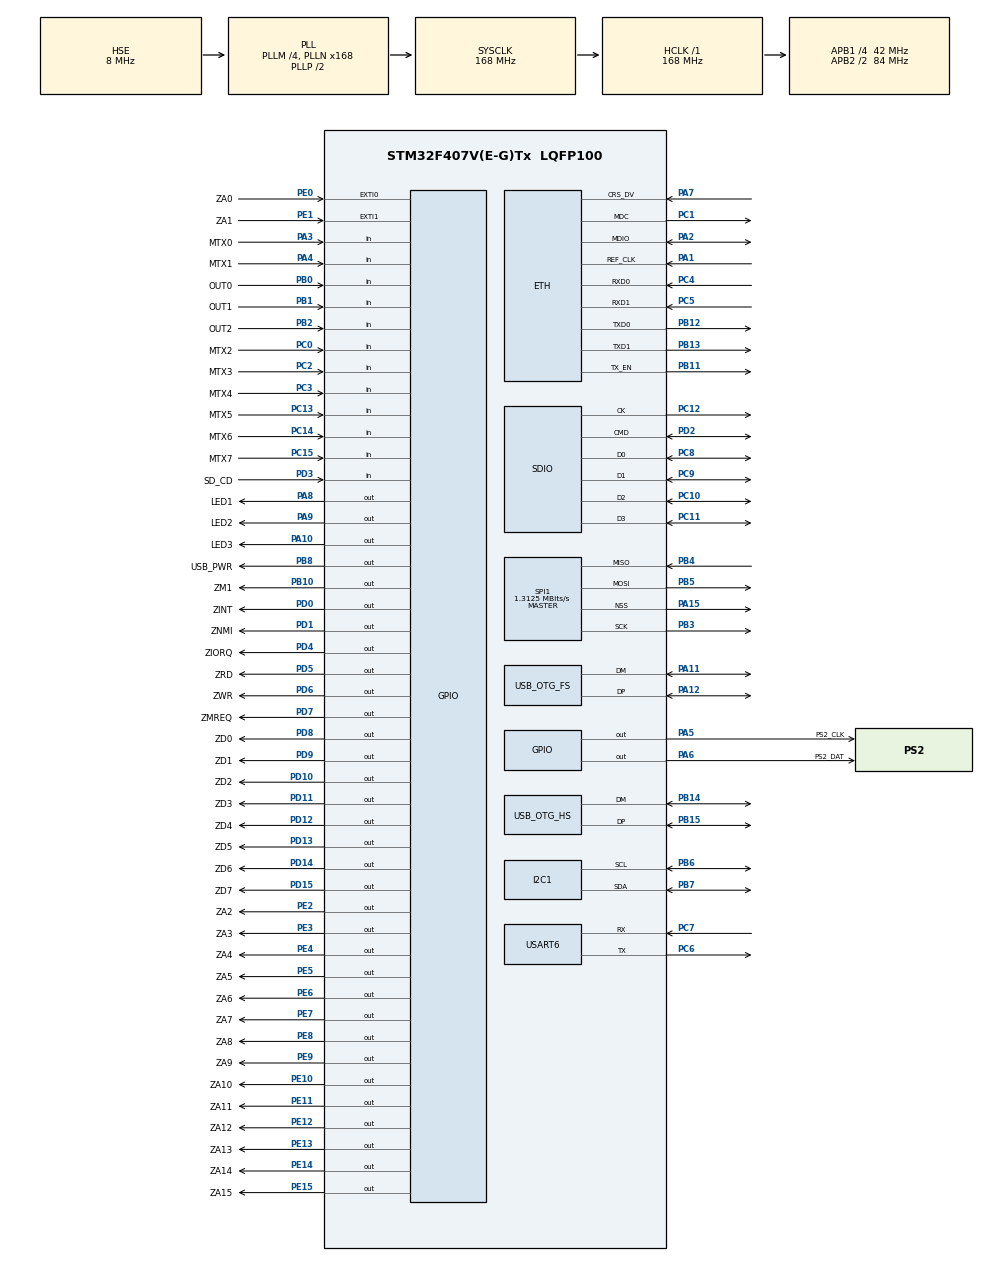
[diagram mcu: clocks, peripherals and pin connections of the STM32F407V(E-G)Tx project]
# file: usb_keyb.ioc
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ETH.MediaInterface=ETH_MEDIA_INTERFACE_RMII
FATFS.BSP.number=1
FATFS._CODE_PAGE=855
FATFS._FS_LOCK=0
FATFS._FS_MINIMIZE=3
FATFS._FS_READONLY=0
FATFS._HUSBH=hUsbHostFS
FATFS._USE_FIND=1
FATFS._USE_LFN=2
FATFS._USE_MKFS=0
FATFS._USE_STRFUNC=0
FATFS0.BSP.STBoard=false
FATFS0.BSP.api=UnknownBspDriver
FATFS0.BSP.i2caddr=0
FATFS0.BSP.i2creg=0
FATFS0.BSP.instance=PD3
FATFS0.BSP.ip=GPIO
FATFS0.BSP.mode=Input
FATFS0.BSP.name=Detect_SDIO
FATFS0.BSP.solution=PD3
Mcu.Family=STM32F4
Mcu.Name=STM32F407V(E-G)Tx
Mcu.Package=LQFP100
NVIC.EXTI0_IRQn=true\:0\:0\:false\:true\:true\:1\:true
NVIC.EXTI1_IRQn=true\:0\:0\:false\:true\:true\:2\:true
NVIC.FLASH_IRQn=true\:0\:0\:false\:false\:true\:true
NVIC.I2C1_ER_IRQn=true\:0\:0\:false\:false\:true\:true
NVIC.I2C1_EV_IRQn=true\:0\:0\:false\:false\:true\:true
NVIC.OTG_FS_IRQn=true\:0\:0\:false\:false\:true\:false
NVIC.OTG_HS_IRQn=true\:0\:0\:false\:false\:true\:false
NVIC.PriorityGroup=NVIC_PRIORITYGROUP_4
NVIC.RCC_IRQn=true\:0\:0\:false\:false\:true\:true
NVIC.SDIO_IRQn=true\:0\:0\:false\:true\:true\:4\:true
NVIC.SPI1_IRQn=true\:0\:0\:false\:false\:true\:true
NVIC.TIM2_IRQn=true\:0\:0\:false\:true\:true\:3\:true
NVIC.TIM4_IRQn=true\:15\:0\:true\:false\:true\:true
NVIC.USART6_IRQn=true\:0\:0\:false\:false\:true\:true
PA1.Mode=RMII
PA1.Signal=ETH_REF_CLK
PA10.GPIO_Label=LED3
PA10.GPIO_PuPd=GPIO_PULLUP
PA10.Signal=GPIO_Output
PA11.Mode=Host_Only
PA11.Signal=USB_OTG_FS_DM
PA12.Mode=Host_Only
PA12.Signal=USB_OTG_FS_DP
PA13.Mode=Serial_Wire
PA13.Signal=SYS_JTMS-SWDIO
PA14.Mode=Serial_Wire
PA14.Signal=SYS_JTCK-SWCLK
PA15.Mode=NSS_Signal_Hard_Output
PA15.Signal=SPI1_NSS
PA2.Mode=RMII
PA2.Signal=ETH_MDIO
PA3.GPIO_Label=MTX0
PA3.GPIO_PuPd=GPIO_PULLUP
PA3.Signal=GPIO_Input
PA4.GPIO_Label=MTX1
PA4.GPIO_PuPd=GPIO_PULLUP
PA4.Signal=GPIO_Input
PA5.GPIO_Label=PS2_CLK
PA5.Signal=GPIO_Output
PA6.GPIO_Label=PS2_DAT
PA6.Signal=GPIO_Output
PA7.Mode=RMII
PA7.Signal=ETH_CRS_DV
PA8.GPIO_Label=LED1
PA8.GPIO_PuPd=GPIO_PULLUP
PA8.Signal=GPIO_Output
PA9.GPIO_Label=LED2
PA9.GPIO_PuPd=GPIO_PULLUP
PA9.Signal=GPIO_Output
PB0.GPIO_Label=OUT0
PB0.GPIO_PuPd=GPIO_PULLUP
PB0.Signal=GPIO_Input
PB1.GPIO_Label=OUT1
PB1.GPIO_PuPd=GPIO_PULLUP
PB1.Signal=GPIO_Input
PB10.GPIO_Label=ZM1
PB10.GPIO_ModeDefaultOutputPP=GPIO_MODE_OUTPUT_OD
PB10.GPIO_Speed=GPIO_SPEED_FREQ_VERY_HIGH
PB10.Signal=GPIO_Output
PB11.Mode=RMII
PB11.Signal=ETH_TX_EN
PB12.Mode=RMII
PB12.Signal=ETH_TXD0
PB13.Mode=RMII
PB13.Signal=ETH_TXD1
PB14.Mode=Host_FS
PB14.Signal=USB_OTG_HS_DM
PB15.Mode=Host_FS
PB15.Signal=USB_OTG_HS_DP
PB2.GPIO_Label=OUT2
PB2.GPIO_PuPd=GPIO_PULLUP
PB2.Signal=GPIO_Input
PB3.Mode=Full_Duplex_Master
PB3.Signal=SPI1_SCK
PB4.Mode=Full_Duplex_Master
PB4.Signal=SPI1_MISO
PB5.Mode=Full_Duplex_Master
PB5.Signal=SPI1_MOSI
PB6.Mode=I2C
PB6.Signal=I2C1_SCL
PB7.Mode=I2C
PB7.Signal=I2C1_SDA
PB8.GPIO_Label=USB_PWR
PB8.Signal=GPIO_Output
PC0.GPIO_Label=MTX2
PC0.GPIO_PuPd=GPIO_PULLUP
PC0.Signal=GPIO_Input
PC1.Mode=RMII
PC1.Signal=ETH_MDC
PC10.Mode=SD_4_bits_Wide_bus
PC10.Signal=SDIO_D2
PC11.Mode=SD_4_bits_Wide_bus
PC11.Signal=SDIO_D3
PC12.Mode=SD_4_bits_Wide_bus
PC12.Signal=SDIO_CK
PC13-ANTI_TAMP.GPIO_Label=MTX5
PC13-ANTI_TAMP.GPIO_PuPd=GPIO_PULLUP
PC13-ANTI_TAMP.Signal=GPIO_Input
PC14-OSC32_IN.GPIO_Label=MTX6
PC14-OSC32_IN.GPIO_PuPd=GPIO_PULLUP
PC14-OSC32_IN.Signal=GPIO_Input
PC15-OSC32_OUT.GPIO_Label=MTX7
PC15-OSC32_OUT.GPIO_PuPd=GPIO_PULLUP
PC15-OSC32_OUT.Signal=GPIO_Input
PC2.GPIO_Label=MTX3
PC2.GPIO_PuPd=GPIO_PULLUP
PC2.Signal=GPIO_Input
PC3.GPIO_Label=MTX4
PC3.GPIO_PuPd=GPIO_PULLUP
PC3.Signal=GPIO_Input
PC4.Mode=RMII
PC4.Signal=ETH_RXD0
PC5.Mode=RMII
PC5.Signal=ETH_RXD1
PC6.Mode=Asynchronous
PC6.Signal=USART6_TX
PC7.Mode=Asynchronous
PC7.Signal=USART6_RX
PC8.Mode=SD_4_bits_Wide_bus
PC8.Signal=SDIO_D0
PC9.Mode=SD_4_bits_Wide_bus
PC9.Signal=SDIO_D1
PD0.GPIO_Label=ZINT
PD0.GPIO_ModeDefaultOutputPP=GPIO_MODE_OUTPUT_OD
PD0.GPIO_Speed=GPIO_SPEED_FREQ_VERY_HIGH
PD0.Signal=GPIO_Output
PD1.GPIO_Label=ZNMI
PD1.GPIO_ModeDefaultOutputPP=GPIO_MODE_OUTPUT_OD
PD1.GPIO_Speed=GPIO_SPEED_FREQ_VERY_HIGH
PD1.Signal=GPIO_Output
PD10.GPIO_Label=ZD2
PD10.GPIO_ModeDefaultOutputPP=GPIO_MODE_OUTPUT_OD
PD10.GPIO_Speed=GPIO_SPEED_FREQ_VERY_HIGH
PD10.Signal=GPIO_Output
PD11.GPIO_Label=ZD3
PD11.GPIO_ModeDefaultOutputPP=GPIO_MODE_OUTPUT_OD
PD11.GPIO_Speed=GPIO_SPEED_FREQ_VERY_HIGH
PD11.Signal=GPIO_Output
PD12.GPIO_Label=ZD4
PD12.GPIO_ModeDefaultOutputPP=GPIO_MODE_OUTPUT_OD
PD12.GPIO_Speed=GPIO_SPEED_FREQ_VERY_HIGH
PD12.Signal=GPIO_Output
PD13.GPIO_Label=ZD5
PD13.GPIO_ModeDefaultOutputPP=GPIO_MODE_OUTPUT_OD
PD13.GPIO_Speed=GPIO_SPEED_FREQ_VERY_HIGH
PD13.Signal=GPIO_Output
PD14.GPIO_Label=ZD6
PD14.GPIO_ModeDefaultOutputPP=GPIO_MODE_OUTPUT_OD
PD14.GPIO_Speed=GPIO_SPEED_FREQ_VERY_HIGH
PD14.Signal=GPIO_Output
PD15.GPIO_Label=ZD7
PD15.GPIO_ModeDefaultOutputPP=GPIO_MODE_OUTPUT_OD
PD15.GPIO_Speed=GPIO_SPEED_FREQ_VERY_HIGH
PD15.Signal=GPIO_Output
PD2.Mode=SD_4_bits_Wide_bus
PD2.Signal=SDIO_CMD
PD3.GPIO_Label=SD_CD
PD3.GPIO_PuPd=GPIO_PULLUP
PD3.Signal=GPIO_Input
PD4.GPIO_Label=ZIORQ
PD4.GPIO_ModeDefaultOutputPP=GPIO_MODE_OUTPUT_OD
PD4.GPIO_Speed=GPIO_SPEED_FREQ_VERY_HIGH
PD4.Signal=GPIO_Output
PD5.GPIO_Label=ZRD
PD5.GPIO_ModeDefaultOutputPP=GPIO_MODE_OUTPUT_OD
PD5.GPIO_Speed=GPIO_SPEED_FREQ_VERY_HIGH
PD5.Signal=GPIO_Output
PD6.GPIO_Label=ZWR
PD6.GPIO_ModeDefaultOutputPP=GPIO_MODE_OUTPUT_OD
PD6.GPIO_Speed=GPIO_SPEED_FREQ_VERY_HIGH
PD6.Signal=GPIO_Output
PD7.GPIO_Label=ZMREQ
PD7.GPIO_ModeDefaultOutputPP=GPIO_MODE_OUTPUT_OD
PD7.GPIO_Speed=GPIO_SPEED_FREQ_VERY_HIGH
PD7.Signal=GPIO_Output
PD8.GPIO_Label=ZD0
PD8.GPIO_ModeDefaultOutputPP=GPIO_MODE_OUTPUT_OD
PD8.GPIO_Speed=GPIO_SPEED_FREQ_VERY_HIGH
PD8.Signal=GPIO_Output
PD9.GPIO_Label=ZD1
PD9.GPIO_ModeDefaultOutputPP=GPIO_MODE_OUTPUT_OD
PD9.GPIO_Speed=GPIO_SPEED_FREQ_VERY_HIGH
PD9.Signal=GPIO_Output
PE0.GPIO_Label=ZA0
PE0.Signal=GPXTI0
PE1.GPIO_Label=ZA1
PE1.Signal=GPXTI1
PE10.GPIO_Label=ZA10
PE10.GPIO_ModeDefaultOutputPP=GPIO_MODE_OUTPUT_OD
PE10.GPIO_Speed=GPIO_SPEED_FREQ_VERY_HIGH
PE10.Signal=GPIO_Output
PE11.GPIO_Label=ZA11
PE11.GPIO_ModeDefaultOutputPP=GPIO_MODE_OUTPUT_OD
PE11.GPIO_Speed=GPIO_SPEED_FREQ_VERY_HIGH
PE11.Signal=GPIO_Output
PE12.GPIO_Label=ZA12
PE12.GPIO_ModeDefaultOutputPP=GPIO_MODE_OUTPUT_OD
PE12.GPIO_Speed=GPIO_SPEED_FREQ_VERY_HIGH
PE12.Signal=GPIO_Output
PE13.GPIO_Label=ZA13
PE13.GPIO_ModeDefaultOutputPP=GPIO_MODE_OUTPUT_OD
PE13.GPIO_Speed=GPIO_SPEED_FREQ_VERY_HIGH
PE13.Signal=GPIO_Output
PE14.GPIO_Label=ZA14
PE14.GPIO_ModeDefaultOutputPP=GPIO_MODE_OUTPUT_OD
PE14.GPIO_Speed=GPIO_SPEED_FREQ_VERY_HIGH
PE14.Signal=GPIO_Output
PE15.GPIO_Label=ZA15
PE15.GPIO_ModeDefaultOutputPP=GPIO_MODE_OUTPUT_OD
PE15.GPIO_Speed=GPIO_SPEED_FREQ_VERY_HIGH
PE15.Signal=GPIO_Output
PE2.GPIO_Label=ZA2
PE2.GPIO_ModeDefaultOutputPP=GPIO_MODE_OUTPUT_OD
PE2.GPIO_Speed=GPIO_SPEED_FREQ_VERY_HIGH
PE2.Signal=GPIO_Output
PE3.GPIO_Label=ZA3
PE3.GPIO_ModeDefaultOutputPP=GPIO_MODE_OUTPUT_OD
PE3.GPIO_Speed=GPIO_SPEED_FREQ_VERY_HIGH
PE3.Signal=GPIO_Output
PE4.GPIO_Label=ZA4
PE4.GPIO_ModeDefaultOutputPP=GPIO_MODE_OUTPUT_OD
PE4.GPIO_Speed=GPIO_SPEED_FREQ_VERY_HIGH
PE4.Signal=GPIO_Output
PE5.GPIO_Label=ZA5
PE5.GPIO_ModeDefaultOutputPP=GPIO_MODE_OUTPUT_OD
PE5.GPIO_Speed=GPIO_SPEED_FREQ_VERY_HIGH
PE5.Signal=GPIO_Output
PE6.GPIO_Label=ZA6
PE6.GPIO_ModeDefaultOutputPP=GPIO_MODE_OUTPUT_OD
PE6.GPIO_Speed=GPIO_SPEED_FREQ_VERY_HIGH
PE6.Signal=GPIO_Output
PE7.GPIO_Label=ZA7
PE7.GPIO_ModeDefaultOutputPP=GPIO_MODE_OUTPUT_OD
PE7.GPIO_Speed=GPIO_SPEED_FREQ_VERY_HIGH
PE7.Signal=GPIO_Output
PE8.GPIO_Label=ZA8
PE8.GPIO_ModeDefaultOutputPP=GPIO_MODE_OUTPUT_OD
PE8.GPIO_Speed=GPIO_SPEED_FREQ_VERY_HIGH
PE8.Signal=GPIO_Output
PE9.GPIO_Label=ZA9
PE9.GPIO_ModeDefaultOutputPP=GPIO_MODE_OUTPUT_OD
PE9.GPIO_Speed=GPIO_SPEED_FREQ_VERY_HIGH
PE9.Signal=GPIO_Output
PH0-OSC_IN.Mode=HSE-External-Oscillator
PH0-OSC_IN.Signal=RCC_OSC_IN
PH1-OSC_OUT.Mode=HSE-External-Oscillator
PH1-OSC_OUT.Signal=RCC_OSC_OUT
ProjectManager.HeapSize=0x1000
ProjectManager.StackSize=0x400
ProjectManager.TargetToolchain=MDK-ARM V5
RCC.48MHZClocksFreq_Value=48000000
RCC.AHBFreq_Value=168000000
RCC.APB1CLKDivider=RCC_HCLK_DIV4
RCC.APB1Freq_Value=42000000
RCC.APB1TimFreq_Value=84000000
RCC.APB2CLKDivider=RCC_HCLK_DIV2
RCC.APB2Freq_Value=84000000
RCC.APB2TimFreq_Value=168000000
RCC.CortexFreq_Value=168000000
RCC.EnbaleCSS=true
RCC.HCLKFreq_Value=168000000
RCC.HSE_VALUE=8000000
RCC.HSI_VALUE=16000000
RCC.LSE_VALUE=32768
RCC.PLLM=4
RCC.PLLN=168
RCC.PLLQ=7
RCC.SYSCLKFreq_VALUE=168000000
RCC.SYSCLKSource=RCC_SYSCLKSOURCE_PLLCLK
RCC.VCOOutputFreq_Value=336000000
SPI1.BaudRatePrescaler=SPI_BAUDRATEPRESCALER_64
SPI1.CalculateBaudRate=1.3125 MBits/s
SPI1.Direction=SPI_DIRECTION_2LINES
SPI1.Mode=SPI_MODE_MASTER
SPI1.VirtualNSS=VM_NSSHARD
SPI1.VirtualType=VM_MASTER
TIM2.Channel-Output\ Compare1\ No\ Output=TIM_CHANNEL_1
TIM2.Channel-Output\ Compare2\ No\ Output=TIM_CHANNEL_2
TIM2.CounterMode=TIM_COUNTERMODE_CENTERALIGNED3
TIM2.Period=875
TIM2.Prescaler=7
TIM2.Pulse-Output\ Compare1\ No\ Output=437
TIM2.Pulse-Output\ Compare2\ No\ Output=875
TIM2.TIM_MasterOutputTrigger=TIM_TRGO_RESET
TIM4.Period=200
TIM4.Prescaler=42000
USART6.VirtualMode=VM_ASYNC
USB_HOST.BSP.number=1
USB_HOST.USBH_DEBUG_LEVEL-ALL_Classes_HS=0
USB_HOST.USBH_HandleTypeDef-ALL_Classes_FS=hUsbHostFS
USB_HOST.USBH_HandleTypeDef-ALL_Classes_HS=hUsbHostHS
USB_HOST.USBH_PROCESS_STACK_SIZE-ALL_Classes_HS=1024
USB_HOST.VirtualModeFS=All_Classes
USB_HOST.VirtualModeHS=All_Classes
USB_HOST0.BSP.STBoard=false
USB_HOST0.BSP.api=UnknownBspDriver
USB_HOST0.BSP.i2caddr=0
USB_HOST0.BSP.i2creg=0
USB_HOST0.BSP.instance=PB8
USB_HOST0.BSP.ip=GPIO
USB_HOST0.BSP.mode=Output
USB_HOST0.BSP.name=Drive_VBUS_FS
USB_HOST0.BSP.solution=PB8
USB_OTG_FS.Sof_enable=DISABLE
USB_OTG_FS.VirtualMode=Host_Only
USB_OTG_FS.phy_itface=HCD_PHY_EMBEDDED
USB_OTG_FS.speed=HCD_SPEED_FULL
USB_OTG_HS.VirtualMode-Host_FS=Host_FS
USB_OTG_HS.dma_enable-Host_FS=DISABLE
VP_FATFS_VS_SDIO.Mode=SDIO
VP_FATFS_VS_USB.Mode=USB
VP_IWDG_VS_IWDG.Mode=IWDG_Activate
VP_TIM2_VS_ClockSourceINT.Mode=Internal
VP_TIM2_VS_no_output1.Mode=Output Compare1 No Output
VP_TIM2_VS_no_output2.Mode=Output Compare2 No Output
VP_TIM4_VS_ClockSourceINT.Mode=Internal
VP_USB_HOST_VS_USB_HOST_ALL_CLASS_FS.Mode=ALL_Classes_FS
VP_USB_HOST_VS_USB_HOST_ALL_CLASS_HS.Mode=ALL_Classes_HS
board=usb_keyb

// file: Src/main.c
/**
  ******************************************************************************
  * @file           : main.c
  * @brief          : Main program body
  ******************************************************************************
  * This notice applies to any and all portions of this file
  * that are not between comment pairs USER CODE BEGIN and
  * USER CODE END. Other portions of this file, whether
  * inserted by the user or by software development tools
  * are owned by their respective copyright owners.
  *
  * Copyright (c) 2018 STMicroelectronics International N.V.
  * All rights reserved.
  *
  * Redistribution and use in source and binary forms, with or without
  * modification, are permitted, provided that the following conditions are met:
  *
  * 1. Redistribution of source code must retain the above copyright notice,
  *    this list of conditions and the following disclaimer.
  * 2. Redistributions in binary form must reproduce the above copyright notice,
  *    this list of conditions and the following disclaimer in the documentation
  *    and/or other materials provided with the distribution.
  * 3. Neither the name of STMicroelectronics nor the names of other
  *    contributors to this software may be used to endorse or promote products
  *    derived from this software without specific written permission.
  * 4. This software, including modifications and/or derivative works of this
  *    software, must execute solely and exclusively on microcontroller or
  *    microprocessor devices manufactured by or for STMicroelectronics.
  * 5. Redistribution and use of this software other than as permitted under
  *    this license is void and will automatically terminate your rights under
  *    this license.
  *
  * THIS SOFTWARE IS PROVIDED BY STMICROELECTRONICS AND CONTRIBUTORS "AS IS"
  * AND ANY EXPRESS, IMPLIED OR STATUTORY WARRANTIES, INCLUDING, BUT NOT
  * LIMITED TO, THE IMPLIED WARRANTIES OF MERCHANTABILITY, FITNESS FOR A
  * PARTICULAR PURPOSE AND NON-INFRINGEMENT OF THIRD PARTY INTELLECTUAL PROPERTY
  * RIGHTS ARE DISCLAIMED TO THE FULLEST EXTENT PERMITTED BY LAW. IN NO EVENT
  * SHALL STMICROELECTRONICS OR CONTRIBUTORS BE LIABLE FOR ANY DIRECT, INDIRECT,
  * INCIDENTAL, SPECIAL, EXEMPLARY, OR CONSEQUENTIAL DAMAGES (INCLUDING, BUT NOT
  * LIMITED TO, PROCUREMENT OF SUBSTITUTE GOODS OR SERVICES; LOSS OF USE, DATA,
  * OR PROFITS; OR BUSINESS INTERRUPTION) HOWEVER CAUSED AND ON ANY THEORY OF
  * LIABILITY, WHETHER IN CONTRACT, STRICT LIABILITY, OR TORT (INCLUDING
  * NEGLIGENCE OR OTHERWISE) ARISING IN ANY WAY OUT OF THE USE OF THIS SOFTWARE,
  * EVEN IF ADVISED OF THE POSSIBILITY OF SUCH DAMAGE.
  *
  ******************************************************************************
  */
#include "main.h"
#include "stm32f4xx_hal.h"
#include "fatfs.h"
#include "usb_host.h"

/* USER CODE BEGIN Includes */
#include "gui_all.h"
#include "kbd_global.h"
/* USER CODE END Includes */

ETH_HandleTypeDef heth;

I2C_HandleTypeDef hi2c1;

IWDG_HandleTypeDef hiwdg;

SD_HandleTypeDef hsd;

SPI_HandleTypeDef hspi1;

TIM_HandleTypeDef htim2;
TIM_HandleTypeDef htim4;

UART_HandleTypeDef huart6;

/* USER CODE BEGIN PV */
/* Private variables ---------------------------------------------------------*/

const kbd_proc_t proc_dummy =
{
	.init = NULL,
	.proc = NULL,
	.interrupt = NULL,
	.periodic = NULL
};

kbd_proc_t out_proc =
{
	.init = NULL,
	.proc = NULL,
	.interrupt = NULL,
	.periodic = NULL
};

/* USER CODE END PV */

void SystemClock_Config(void);
static void MX_GPIO_Init(void);
static void MX_IWDG_Init(void);
static void MX_SDIO_SD_Init(void);
static void MX_TIM4_Init(void);
static void MX_USART6_UART_Init(void);
static void MX_TIM2_Init(void);
static void MX_SPI1_Init(void);
static void MX_I2C1_Init(void);
static void MX_ETH_Init(void);
static void MX_NVIC_Init(void);
void MX_USB_HOST_Process(void);

/* USER CODE BEGIN PFP */
/* Private function prototypes -----------------------------------------------*/
void LCD_fill_mem(void);

uint8_t usb_mode = SW_MODE_PS2;
uint8_t running = 0;
/* USER CODE END PFP */

/* USER CODE BEGIN 0 */

extern USBH_HandleTypeDef hUsbHostHS;
extern USBH_HandleTypeDef hUsbHostFS;

void read_config(void)
{
	usb_mode = 0;
	usb_mode |= HAL_GPIO_ReadPin(OUT0_GPIO_Port, OUT0_Pin) << 2;
	usb_mode |= HAL_GPIO_ReadPin(OUT1_GPIO_Port, OUT1_Pin) << 1;
	usb_mode |= HAL_GPIO_ReadPin(OUT2_GPIO_Port, OUT2_Pin) << 0;

	matrix_mode = 0;
	matrix_mode |= HAL_GPIO_ReadPin(MTX0_GPIO_Port, MTX0_Pin) << 7;
	matrix_mode |= HAL_GPIO_ReadPin(MTX1_GPIO_Port, MTX1_Pin) << 6;
	matrix_mode |= HAL_GPIO_ReadPin(MTX2_GPIO_Port, MTX2_Pin) << 5;
	matrix_mode |= HAL_GPIO_ReadPin(MTX3_GPIO_Port, MTX3_Pin) << 4;
	matrix_mode |= HAL_GPIO_ReadPin(MTX4_GPIO_Port, MTX4_Pin) << 3;
	matrix_mode |= HAL_GPIO_ReadPin(MTX5_GPIO_Port, MTX5_Pin) << 2;
	matrix_mode |= HAL_GPIO_ReadPin(MTX6_GPIO_Port, MTX6_Pin) << 1;
	matrix_mode |= HAL_GPIO_ReadPin(MTX7_GPIO_Port, MTX7_Pin) << 0;
}

int fputc(int ch, FILE *f)
{
  /* Place your implementation of fputc here */
  /* e.g. write a character to the USART1 and Loop until the end of transmission */
  HAL_UART_Transmit(&huart6, (uint8_t *)&ch, 1, 0xFFFF);

  return ch;
}

/* USER CODE END 0 */

int main(void)
{

  /* MCU Configuration----------------------------------------------------------*/

  /* Reset of all peripherals, Initializes the Flash interface and the Systick. */
  HAL_Init();
	__enable_irq();

  /* Configure the system clock */
  SystemClock_Config();

  /* Initialize all configured peripherals */
  MX_GPIO_Init();
	#ifdef IWDG_USE
  MX_IWDG_Init();
	#endif
  MX_SDIO_SD_Init();
  MX_FATFS_Init();
  MX_USB_HOST_Init();
  MX_TIM4_Init();
  MX_USART6_UART_Init();
  MX_TIM2_Init();
  MX_SPI1_Init();
  MX_I2C1_Init();
  //MX_ETH_Init();

  /* Initialize interrupts */
  MX_NVIC_Init();
  /* USER CODE BEGIN 2 */
	DEBUG_PR("\n\rUSB keboard module (v%i)\n\r", KBD_VERSION);

	read_config();
	matrix_sel();
	uint8_t mounted = 0;

	DEBUG_PR("Matrix: #%i\n\r", matrix_mode);
	DEBUG_PR("Mode: #%i\n\r", usb_mode);
	switch (usb_mode)
	{
	case SW_MODE_PS2:
		DEBUG_PR("Mode: PS/2\n\r");
		out_proc = proc_ps2;
		break;
	case SW_MODE_ZXBUS:
		DEBUG_PR("Mode: ZX-BUS\n\r");
		out_proc = proc_zxbus;
		break;
	case SW_MODE_ORION:
		DEBUG_PR("Mode: ORION-NG\n\r");
		out_proc = proc_orion;
		break;
	case SW_MODE_MATRIX:
	default:
		DEBUG_PR("Mode: matrix\n\r");
		out_proc = proc_matrix;
		break;
	}
	if (out_proc.init != NULL)
		out_proc.init();
	running = 1;

	HAL_GPIO_WritePin(LED1_GPIO_Port, LED1_Pin, GPIO_PIN_RESET);
	HAL_GPIO_WritePin(LED2_GPIO_Port, LED2_Pin, GPIO_PIN_RESET);
	HAL_GPIO_WritePin(LED3_GPIO_Port, LED3_Pin, GPIO_PIN_RESET);
  /* USER CODE END 2 */

  /* Infinite loop */
  /* USER CODE BEGIN WHILE */
	if (f_mount(&SDFatFS, SDPath, 1) == FR_OK)
	{
		printf("Mount SD OK\n\r");
	}

  while (1)
  {
		if (out_proc.proc != NULL)
			out_proc.proc();

  /* USER CODE END WHILE */
    MX_USB_HOST_Process();

  }

}

void SystemClock_Config(void)
{

  RCC_OscInitTypeDef RCC_OscInitStruct;
  RCC_ClkInitTypeDef RCC_ClkInitStruct;

    /**Configure the main internal regulator output voltage
    */
  __HAL_RCC_PWR_CLK_ENABLE();

  __HAL_PWR_VOLTAGESCALING_CONFIG(PWR_REGULATOR_VOLTAGE_SCALE1);

    /**Initializes the CPU, AHB and APB busses clocks
    */
  RCC_OscInitStruct.OscillatorType = RCC_OSCILLATORTYPE_LSI|RCC_OSCILLATORTYPE_HSE;
  RCC_OscInitStruct.HSEState = RCC_HSE_ON;
  RCC_OscInitStruct.LSIState = RCC_LSI_ON;
  RCC_OscInitStruct.PLL.PLLState = RCC_PLL_ON;
  RCC_OscInitStruct.PLL.PLLSource = RCC_PLLSOURCE_HSE;
  RCC_OscInitStruct.PLL.PLLM = 4;
  RCC_OscInitStruct.PLL.PLLN = 168;
  RCC_OscInitStruct.PLL.PLLP = RCC_PLLP_DIV2;
  RCC_OscInitStruct.PLL.PLLQ = 7;
  if (HAL_RCC_OscConfig(&RCC_OscInitStruct) != HAL_OK)
  {
    _Error_Handler(__FILE__, __LINE__);
  }

    /**Initializes the CPU, AHB and APB busses clocks
    */
  RCC_ClkInitStruct.ClockType = RCC_CLOCKTYPE_HCLK|RCC_CLOCKTYPE_SYSCLK
                              |RCC_CLOCKTYPE_PCLK1|RCC_CLOCKTYPE_PCLK2;
  RCC_ClkInitStruct.SYSCLKSource = RCC_SYSCLKSOURCE_PLLCLK;
  RCC_ClkInitStruct.AHBCLKDivider = RCC_SYSCLK_DIV1;
  RCC_ClkInitStruct.APB1CLKDivider = RCC_HCLK_DIV4;
  RCC_ClkInitStruct.APB2CLKDivider = RCC_HCLK_DIV2;

  if (HAL_RCC_ClockConfig(&RCC_ClkInitStruct, FLASH_LATENCY_5) != HAL_OK)
  {
    _Error_Handler(__FILE__, __LINE__);
  }

    /**Enables the Clock Security System
    */
  HAL_RCC_EnableCSS();

    /**Configure the Systick interrupt time
    */
  HAL_SYSTICK_Config(HAL_RCC_GetHCLKFreq()/1000);

    /**Configure the Systick
    */
  HAL_SYSTICK_CLKSourceConfig(SYSTICK_CLKSOURCE_HCLK);

  /* SysTick_IRQn interrupt configuration */
  HAL_NVIC_SetPriority(SysTick_IRQn, 0, 0);
}

/**
  * @brief NVIC Configuration.
  * @retval None
  */
static void MX_NVIC_Init(void)
{
  /* EXTI0_IRQn interrupt configuration */
  HAL_NVIC_SetPriority(EXTI0_IRQn, 0, 0);
  HAL_NVIC_EnableIRQ(EXTI0_IRQn);
  /* EXTI1_IRQn interrupt configuration */
  HAL_NVIC_SetPriority(EXTI1_IRQn, 0, 0);
  HAL_NVIC_EnableIRQ(EXTI1_IRQn);
  /* TIM2_IRQn interrupt configuration */
  HAL_NVIC_SetPriority(TIM2_IRQn, 0, 0);
  HAL_NVIC_EnableIRQ(TIM2_IRQn);
  /* SDIO_IRQn interrupt configuration */
  HAL_NVIC_SetPriority(SDIO_IRQn, 0, 0);
  HAL_NVIC_EnableIRQ(SDIO_IRQn);
}

/* ETH init function */
static void MX_ETH_Init(void)
{

   uint8_t MACAddr[6] ;

  heth.Instance = ETH;
  heth.Init.AutoNegotiation = ETH_AUTONEGOTIATION_ENABLE;
  heth.Init.PhyAddress = LAN8742A_PHY_ADDRESS;
  MACAddr[0] = 0x00;
  MACAddr[1] = 0x80;
  MACAddr[2] = 0xE1;
  MACAddr[3] = 0x00;
  MACAddr[4] = 0x00;
  MACAddr[5] = 0x00;
  heth.Init.MACAddr = &MACAddr[0];
  heth.Init.RxMode = ETH_RXPOLLING_MODE;
  heth.Init.ChecksumMode = ETH_CHECKSUM_BY_HARDWARE;
  heth.Init.MediaInterface = ETH_MEDIA_INTERFACE_RMII;

  if (HAL_ETH_Init(&heth) != HAL_OK)
  {
    _Error_Handler(__FILE__, __LINE__);
  }

}

/* I2C1 init function */
static void MX_I2C1_Init(void)
{

  hi2c1.Instance = I2C1;
  hi2c1.Init.ClockSpeed = 100000;
  hi2c1.Init.DutyCycle = I2C_DUTYCYCLE_2;
  hi2c1.Init.OwnAddress1 = 0;
  hi2c1.Init.AddressingMode = I2C_ADDRESSINGMODE_7BIT;
  hi2c1.Init.DualAddressMode = I2C_DUALADDRESS_DISABLE;
  hi2c1.Init.OwnAddress2 = 0;
  hi2c1.Init.GeneralCallMode = I2C_GENERALCALL_DISABLE;
  hi2c1.Init.NoStretchMode = I2C_NOSTRETCH_DISABLE;
  if (HAL_I2C_Init(&hi2c1) != HAL_OK)
  {
    _Error_Handler(__FILE__, __LINE__);
  }

}

/* IWDG init function */
static void MX_IWDG_Init(void)
{

  hiwdg.Instance = IWDG;
  hiwdg.Init.Prescaler = IWDG_PRESCALER_4;
  hiwdg.Init.Reload = 4095;
  if (HAL_IWDG_Init(&hiwdg) != HAL_OK)
  {
    _Error_Handler(__FILE__, __LINE__);
  }

}

/* SDIO init function */
static void MX_SDIO_SD_Init(void)
{

  hsd.Instance = SDIO;
  hsd.Init.ClockEdge = SDIO_CLOCK_EDGE_RISING;
  hsd.Init.ClockBypass = SDIO_CLOCK_BYPASS_DISABLE;
  hsd.Init.ClockPowerSave = SDIO_CLOCK_POWER_SAVE_DISABLE;
  hsd.Init.BusWide = SDIO_BUS_WIDE_1B;
  hsd.Init.HardwareFlowControl = SDIO_HARDWARE_FLOW_CONTROL_DISABLE;
  hsd.Init.ClockDiv = 0;

}

/* SPI1 init function */
static void MX_SPI1_Init(void)
{

  /* SPI1 parameter configuration*/
  hspi1.Instance = SPI1;
  hspi1.Init.Mode = SPI_MODE_MASTER;
  hspi1.Init.Direction = SPI_DIRECTION_2LINES;
  hspi1.Init.DataSize = SPI_DATASIZE_8BIT;
  hspi1.Init.CLKPolarity = SPI_POLARITY_LOW;
  hspi1.Init.CLKPhase = SPI_PHASE_1EDGE;
  hspi1.Init.NSS = SPI_NSS_HARD_OUTPUT;
  hspi1.Init.BaudRatePrescaler = SPI_BAUDRATEPRESCALER_2;
  hspi1.Init.FirstBit = SPI_FIRSTBIT_MSB;
  hspi1.Init.TIMode = SPI_TIMODE_DISABLE;
  hspi1.Init.CRCCalculation = SPI_CRCCALCULATION_DISABLE;
  hspi1.Init.CRCPolynomial = 10;
  if (HAL_SPI_Init(&hspi1) != HAL_OK)
  {
    _Error_Handler(__FILE__, __LINE__);
  }

}

/* TIM2 init function */
static void MX_TIM2_Init(void)
{

  TIM_ClockConfigTypeDef sClockSourceConfig;
  TIM_MasterConfigTypeDef sMasterConfig;
  TIM_OC_InitTypeDef sConfigOC;

  htim2.Instance = TIM2;
  htim2.Init.Prescaler = PS2_CLK_PRESCALER - 1;
  htim2.Init.CounterMode = TIM_COUNTERMODE_CENTERALIGNED3;
  htim2.Init.Period = (PS2_CLK_PERIOD / 2) - 1;
  htim2.Init.ClockDivision = TIM_CLOCKDIVISION_DIV1;
  if (HAL_TIM_Base_Init(&htim2) != HAL_OK)
  {
    _Error_Handler(__FILE__, __LINE__);
  }

  sClockSourceConfig.ClockSource = TIM_CLOCKSOURCE_INTERNAL;
  if (HAL_TIM_ConfigClockSource(&htim2, &sClockSourceConfig) != HAL_OK)
  {
    _Error_Handler(__FILE__, __LINE__);
  }

  if (HAL_TIM_OC_Init(&htim2) != HAL_OK)
  {
    _Error_Handler(__FILE__, __LINE__);
  }

  sMasterConfig.MasterOutputTrigger = TIM_TRGO_RESET;
  sMasterConfig.MasterSlaveMode = TIM_MASTERSLAVEMODE_DISABLE;
  if (HAL_TIMEx_MasterConfigSynchronization(&htim2, &sMasterConfig) != HAL_OK)
  {
    _Error_Handler(__FILE__, __LINE__);
  }

  sConfigOC.OCMode = TIM_OCMODE_TIMING;
  sConfigOC.Pulse = (PS2_CLK_PERIOD / 4) - 1;
  sConfigOC.OCPolarity = TIM_OCPOLARITY_HIGH;
  sConfigOC.OCFastMode = TIM_OCFAST_DISABLE;
  if (HAL_TIM_OC_ConfigChannel(&htim2, &sConfigOC, TIM_CHANNEL_1) != HAL_OK)
  {
    _Error_Handler(__FILE__, __LINE__);
  }

  sConfigOC.Pulse = (PS2_CLK_PERIOD / 2) - 1;
  if (HAL_TIM_OC_ConfigChannel(&htim2, &sConfigOC, TIM_CHANNEL_2) != HAL_OK)
  {
    _Error_Handler(__FILE__, __LINE__);
  }

}

/* TIM4 init function */
static void MX_TIM4_Init(void)
{

  TIM_ClockConfigTypeDef sClockSourceConfig;
  TIM_MasterConfigTypeDef sMasterConfig;

  htim4.Instance = TIM4;
  htim4.Init.Prescaler = 42000;
  htim4.Init.CounterMode = TIM_COUNTERMODE_UP;
  htim4.Init.Period = 200;
  htim4.Init.ClockDivision = TIM_CLOCKDIVISION_DIV1;
  if (HAL_TIM_Base_Init(&htim4) != HAL_OK)
  {
    _Error_Handler(__FILE__, __LINE__);
  }

  sClockSourceConfig.ClockSource = TIM_CLOCKSOURCE_INTERNAL;
  if (HAL_TIM_ConfigClockSource(&htim4, &sClockSourceConfig) != HAL_OK)
  {
    _Error_Handler(__FILE__, __LINE__);
  }

  sMasterConfig.MasterOutputTrigger = TIM_TRGO_RESET;
  sMasterConfig.MasterSlaveMode = TIM_MASTERSLAVEMODE_DISABLE;
  if (HAL_TIMEx_MasterConfigSynchronization(&htim4, &sMasterConfig) != HAL_OK)
  {
    _Error_Handler(__FILE__, __LINE__);
  }

}

/* USART6 init function */
static void MX_USART6_UART_Init(void)
{

  huart6.Instance = USART6;
  huart6.Init.BaudRate = 115200;
  huart6.Init.WordLength = UART_WORDLENGTH_8B;
  huart6.Init.StopBits = UART_STOPBITS_1;
  huart6.Init.Parity = UART_PARITY_NONE;
  huart6.Init.Mode = UART_MODE_TX_RX;
  huart6.Init.HwFlowCtl = UART_HWCONTROL_NONE;
  huart6.Init.OverSampling = UART_OVERSAMPLING_16;
  if (HAL_UART_Init(&huart6) != HAL_OK)
  {
    _Error_Handler(__FILE__, __LINE__);
  }

}

/** Configure pins as
        * Analog
        * Input
        * Output
        * EVENT_OUT
        * EXTI
        * Free pins are configured automatically as Analog (this feature is enabled through
        * the Code Generation settings)
*/
static void MX_GPIO_Init(void)
{

  GPIO_InitTypeDef GPIO_InitStruct;

  /* GPIO Ports Clock Enable */
  __HAL_RCC_GPIOE_CLK_ENABLE();
  __HAL_RCC_GPIOC_CLK_ENABLE();
  __HAL_RCC_GPIOH_CLK_ENABLE();
  __HAL_RCC_GPIOA_CLK_ENABLE();
  __HAL_RCC_GPIOB_CLK_ENABLE();
  __HAL_RCC_GPIOD_CLK_ENABLE();

  /*Configure GPIO pin Output Level */
  HAL_GPIO_WritePin(GPIOE, ZA2_Pin|ZA3_Pin|ZA4_Pin|ZA5_Pin
                          |ZA6_Pin|ZA7_Pin|ZA8_Pin|ZA9_Pin
                          |ZA10_Pin|ZA11_Pin|ZA12_Pin|ZA13_Pin
                          |ZA14_Pin|ZA15_Pin, GPIO_PIN_SET);

  /*Configure GPIO pin Output Level */
  HAL_GPIO_WritePin(GPIOA, PS2_CLK_Pin|PS2_DAT_Pin|LED1_Pin|LED2_Pin
                          |LED3_Pin, GPIO_PIN_RESET);

  /*Configure GPIO pin Output Level */
  HAL_GPIO_WritePin(GPIOB, ZM1_Pin|USB_PWR_Pin, GPIO_PIN_RESET);

  /*Configure GPIO pin Output Level */
  HAL_GPIO_WritePin(GPIOD, ZD0_Pin|ZD1_Pin|ZD2_Pin|ZD3_Pin
                          |ZD4_Pin|ZD5_Pin|ZD6_Pin|ZD7_Pin
                          |ZINT_Pin|ZNMI_Pin|ZIORQ_Pin|ZRD_Pin
                          |ZWR_Pin|ZMREQ_Pin, GPIO_PIN_SET);

  /*Configure GPIO pins : ZA2_Pin ZA3_Pin ZA4_Pin ZA5_Pin
                           ZA6_Pin ZA7_Pin ZA8_Pin ZA9_Pin
                           ZA10_Pin ZA11_Pin ZA12_Pin ZA13_Pin
                           ZA14_Pin ZA15_Pin */
  GPIO_InitStruct.Pin = ZA2_Pin|ZA3_Pin|ZA4_Pin|ZA5_Pin
                          |ZA6_Pin|ZA7_Pin|ZA8_Pin|ZA9_Pin
                          |ZA10_Pin|ZA11_Pin|ZA12_Pin|ZA13_Pin
                          |ZA14_Pin|ZA15_Pin;
  GPIO_InitStruct.Mode = GPIO_MODE_OUTPUT_OD;
  GPIO_InitStruct.Pull = GPIO_NOPULL;
  GPIO_InitStruct.Speed = GPIO_SPEED_FREQ_VERY_HIGH;
  HAL_GPIO_Init(GPIOE, &GPIO_InitStruct);

  /*Configure GPIO pins : MTX5_Pin MTX6_Pin MTX7_Pin MTX2_Pin
                           MTX3_Pin MTX4_Pin */
  GPIO_InitStruct.Pin = MTX5_Pin|MTX6_Pin|MTX7_Pin|MTX2_Pin
                          |MTX3_Pin|MTX4_Pin;
  GPIO_InitStruct.Mode = GPIO_MODE_INPUT;
  GPIO_InitStruct.Pull = GPIO_PULLUP;
  HAL_GPIO_Init(GPIOC, &GPIO_InitStruct);

  /*Configure GPIO pin : PA0 */
  GPIO_InitStruct.Pin = GPIO_PIN_0;
  GPIO_InitStruct.Mode = GPIO_MODE_ANALOG;
  GPIO_InitStruct.Pull = GPIO_NOPULL;
  HAL_GPIO_Init(GPIOA, &GPIO_InitStruct);

  /*Configure GPIO pins : MTX0_Pin MTX1_Pin */
  GPIO_InitStruct.Pin = MTX0_Pin|MTX1_Pin;
  GPIO_InitStruct.Mode = GPIO_MODE_INPUT;
  GPIO_InitStruct.Pull = GPIO_PULLUP;
  HAL_GPIO_Init(GPIOA, &GPIO_InitStruct);

  /*Configure GPIO pins : PS2_CLK_Pin PS2_DAT_Pin */
  GPIO_InitStruct.Pin = PS2_CLK_Pin|PS2_DAT_Pin;
  GPIO_InitStruct.Mode = GPIO_MODE_OUTPUT_PP;
  GPIO_InitStruct.Pull = GPIO_NOPULL;
  GPIO_InitStruct.Speed = GPIO_SPEED_FREQ_LOW;
  HAL_GPIO_Init(GPIOA, &GPIO_InitStruct);

  /*Configure GPIO pins : OUT0_Pin OUT1_Pin OUT2_Pin */
  GPIO_InitStruct.Pin = OUT0_Pin|OUT1_Pin|OUT2_Pin;
  GPIO_InitStruct.Mode = GPIO_MODE_INPUT;
  GPIO_InitStruct.Pull = GPIO_PULLUP;
  HAL_GPIO_Init(GPIOB, &GPIO_InitStruct);

  /*Configure GPIO pin : ZM1_Pin */
  GPIO_InitStruct.Pin = ZM1_Pin;
  GPIO_InitStruct.Mode = GPIO_MODE_OUTPUT_OD;
  GPIO_InitStruct.Pull = GPIO_NOPULL;
  GPIO_InitStruct.Speed = GPIO_SPEED_FREQ_VERY_HIGH;
  HAL_GPIO_Init(ZM1_GPIO_Port, &GPIO_InitStruct);

  /*Configure GPIO pins : ZD0_Pin ZD1_Pin ZD2_Pin ZD3_Pin
                           ZD4_Pin ZD5_Pin ZD6_Pin ZD7_Pin
                           ZINT_Pin ZNMI_Pin ZIORQ_Pin ZRD_Pin
                           ZWR_Pin ZMREQ_Pin */
  GPIO_InitStruct.Pin = ZD0_Pin|ZD1_Pin|ZD2_Pin|ZD3_Pin
                          |ZD4_Pin|ZD5_Pin|ZD6_Pin|ZD7_Pin
                          |ZINT_Pin|ZNMI_Pin|ZIORQ_Pin|ZRD_Pin
                          |ZWR_Pin|ZMREQ_Pin;
  GPIO_InitStruct.Mode = GPIO_MODE_OUTPUT_OD;
  GPIO_InitStruct.Pull = GPIO_NOPULL;
  GPIO_InitStruct.Speed = GPIO_SPEED_FREQ_VERY_HIGH;
  HAL_GPIO_Init(GPIOD, &GPIO_InitStruct);

  /*Configure GPIO pins : LED1_Pin LED2_Pin LED3_Pin */
  GPIO_InitStruct.Pin = LED1_Pin|LED2_Pin|LED3_Pin;
  GPIO_InitStruct.Mode = GPIO_MODE_OUTPUT_PP;
  GPIO_InitStruct.Pull = GPIO_PULLUP;
  GPIO_InitStruct.Speed = GPIO_SPEED_FREQ_LOW;
  HAL_GPIO_Init(GPIOA, &GPIO_InitStruct);

  /*Configure GPIO pin : SD_CD_Pin */
  GPIO_InitStruct.Pin = SD_CD_Pin;
  GPIO_InitStruct.Mode = GPIO_MODE_INPUT;
  GPIO_InitStruct.Pull = GPIO_PULLUP;
  HAL_GPIO_Init(SD_CD_GPIO_Port, &GPIO_InitStruct);

  /*Configure GPIO pin : USB_PWR_Pin */
  GPIO_InitStruct.Pin = USB_PWR_Pin;
  GPIO_InitStruct.Mode = GPIO_MODE_OUTPUT_PP;
  GPIO_InitStruct.Pull = GPIO_NOPULL;
  GPIO_InitStruct.Speed = GPIO_SPEED_FREQ_LOW;
  HAL_GPIO_Init(USB_PWR_GPIO_Port, &GPIO_InitStruct);

  /*Configure GPIO pin : PB9 */
  GPIO_InitStruct.Pin = GPIO_PIN_9;
  GPIO_InitStruct.Mode = GPIO_MODE_ANALOG;
  GPIO_InitStruct.Pull = GPIO_NOPULL;
  HAL_GPIO_Init(GPIOB, &GPIO_InitStruct);

  /*Configure GPIO pins : ZA0_Pin ZA1_Pin */
  GPIO_InitStruct.Pin = ZA0_Pin|ZA1_Pin;
  GPIO_InitStruct.Mode = GPIO_MODE_IT_RISING;
  GPIO_InitStruct.Pull = GPIO_NOPULL;
  HAL_GPIO_Init(GPIOE, &GPIO_InitStruct);

}

/* USER CODE BEGIN 4 */
void HAL_GPIO_EXTI_Callback(uint16_t GPIO_Pin)
{
	__disable_irq();
	GPIOE->BSRR = GPIO_BSRR_BS2;
	if (running)
	{
		HAL_GPIO_TogglePin(LED3_GPIO_Port, LED3_Pin);
		if (out_proc.interrupt != NULL)
			out_proc.interrupt();
	}
	GPIOE->BSRR = GPIO_BSRR_BR2;
	__enable_irq();
}

void HAL_TIM_OC_DelayElapsedCallback(TIM_HandleTypeDef *htim)
{
	if (out_proc.periodic != NULL)
		out_proc.periodic(htim);
}

/* USER CODE END 4 */

void _Error_Handler(char *file, int line)
{
  /* USER CODE BEGIN Error_Handler_Debug */
  /* User can add his own implementation to report the HAL error return state */
  while(1)
  {
		HAL_GPIO_WritePin(LED3_GPIO_Port, LED3_Pin, GPIO_PIN_SET);
  }
  /* USER CODE END Error_Handler_Debug */
}

/************************ (C) COPYRIGHT STMicroelectronics *****END OF FILE****/
